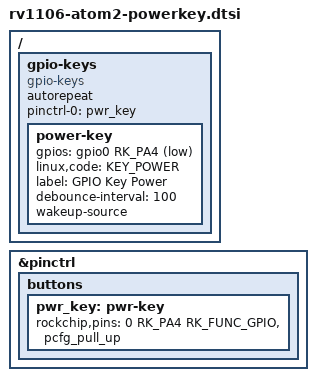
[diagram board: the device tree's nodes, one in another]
// SPDX-License-Identifier: (GPL-2.0+ OR MIT)
/*
 * Copyright (c) 2024 Guangzhou EASY EAI Technology Co., Ltd.
 */

/ {
	gpio-keys {
		compatible = "gpio-keys";
		autorepeat;
		pinctrl-names = "default";
		pinctrl-0 = <&pwr_key>;

		power-key {
				gpios = <&gpio0 RK_PA4 GPIO_ACTIVE_LOW>;
				linux,code = <KEY_POWER>;
				label ="GPIO Key Power";
				debounce-interval = <100>;
				wakeup-source;
		};
	};
};

&pinctrl {
	buttons {
		pwr_key:pwr-key {
			rockchip,pins = <0 RK_PA4 RK_FUNC_GPIO &pcfg_pull_up>;
		};
	};
};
